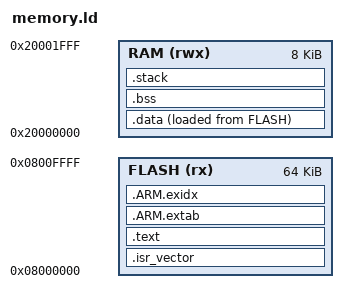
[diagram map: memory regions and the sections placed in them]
/* Generic resource envelope only: replace with the board's real linker script. */
ENTRY(Reset_Handler)
MEMORY
{
    FLASH (rx) : ORIGIN = 0x08000000, LENGTH = 64K
    RAM (rwx) : ORIGIN = 0x20000000, LENGTH = 8K
}
SECTIONS
{
    .isr_vector : { KEEP(*(.isr_vector)) } > FLASH
    .text :
    {
        *(.text .text.*)
        *(.rodata .rodata.*)
        . = ALIGN(4);
    } > FLASH
    .ARM.extab : { *(.ARM.extab*) } > FLASH
    .ARM.exidx : { *(.ARM.exidx*) } > FLASH
    .data :
    {
        . = ALIGN(8);
        __data_start = .;
        *(.data .data.*)
        . = ALIGN(8);
        __data_end = .;
    } > RAM AT> FLASH
    __data_load = LOADADDR(.data);
    .bss (NOLOAD) :
    {
        . = ALIGN(8);
        __bss_start = .;
        *(.bss .bss.* COMMON)
        . = ALIGN(8);
        __bss_end = .;
    } > RAM
    .stack (NOLOAD) :
    {
        . = ALIGN(8);
        __stack_bottom = .;
        . += 1024;
        __stack_top = .;
    } > RAM
    /DISCARD/ : { *(.comment) *(.note*) }
}
ASSERT(__stack_top <= ORIGIN(RAM) + LENGTH(RAM), "RAM plus reserved stack exceeds 8 KiB")
